# STM32F303xE register map
File version: 1.0
Registers are 32-bit, read-write, reset 0x0 unless marked. A register's access mark holds for its fields unless they carry their own. Offsets are from the block's base; [hi:lo] are bit positions; {n}, {i} and the like mark numbered series; 'fields as' and 'values as' point back to an identical list.

## GPIOA — General Purpose I/O
Base 0x48000000
Same registers: GPIOB 0x48000400, GPIOC 0x48000800, GPIOD 0x48000C00, GPIOE 0x48001000, GPIOF 0x48001400, GPIOG 0x48001800, GPIOH 0x48001C00
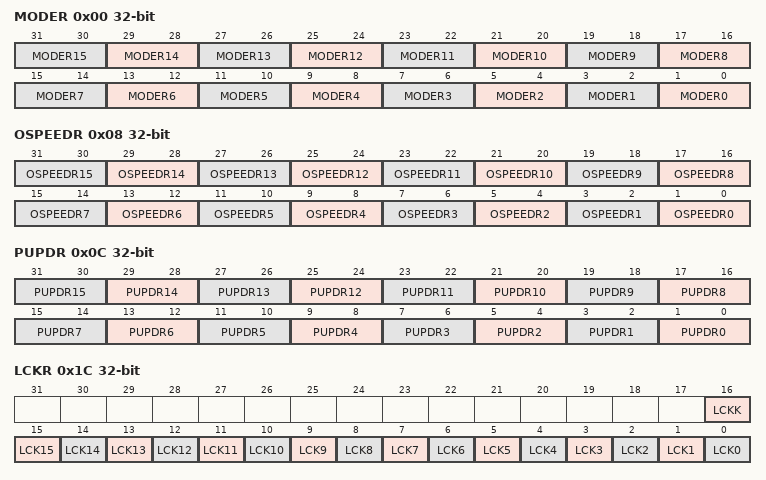
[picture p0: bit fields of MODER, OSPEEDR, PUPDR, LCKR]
0x00 MODER — GPIO port mode register
  [2n+1:2n] MODER{n} (n=0..15)
0x04 OTYPER — GPIO port output type register
0x08 OSPEEDR — GPIO port output speed register
  [2n+1:2n] OSPEEDR{n} (n=0..15)
0x0C PUPDR — GPIO port pull-up/pull-down register
  [2n+1:2n] PUPDR{n} (n=0..15)
0x10 IDR — GPIO port input data register
0x14 ODR — GPIO port output data register
0x18 BSRR — GPIO port bit set/reset register
0x1C LCKR — GPIO port configuration lock register
  [16] LCKK, [n] LCK{n} (n=0..15)
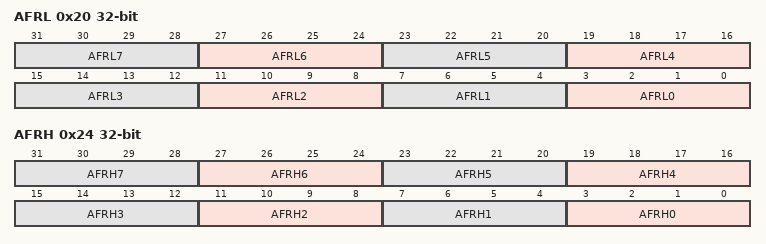
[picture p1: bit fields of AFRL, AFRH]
0x20 AFRL — GPIO alternate function registers
  [4n+3:4n] AFRL{n} (n=0..7)
0x24 AFRH — GPIO alternate function registers
  [4n+3:4n] AFRH{n} (n=0..7)
0x28 BRR — GPIO bit reset register

## FMC_Bank2_3 — Flexible Memory Controller Bank2
Base 0xA0000060
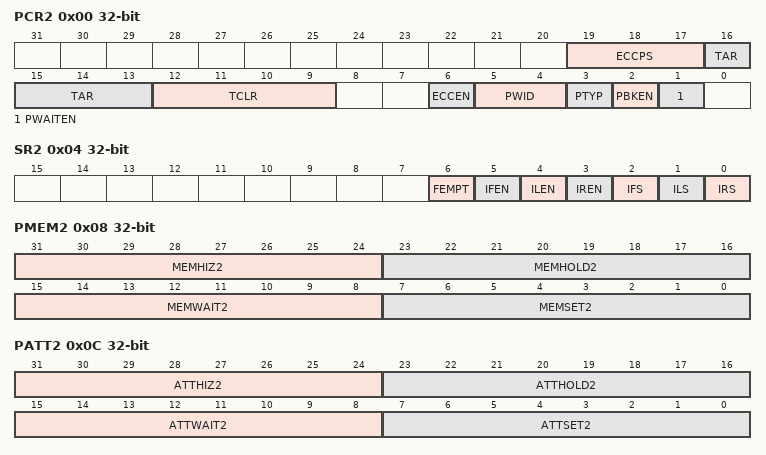
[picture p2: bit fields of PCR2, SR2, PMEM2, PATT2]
0x00 PCR2 — NAND Flash control register 2
  [19:17] ECCPS — ECCPS[1:0] bits (ECC page size)
  [16:13] TAR — TAR[3:0] bits (ALE to RE delay)
  [12:9] TCLR — TCLR[3:0] bits (CLE to RE delay)
  [6] ECCEN — ECC computation logic enable bit
  [5:4] PWID — PWID[1:0] bits (NAND Flash databus width)
  [3] PTYP — Memory type
  [2] PBKEN — PC Card/NAND Flash memory bank enable bit
  [1] PWAITEN — Wait feature enable bit
0x04 SR2 — NAND Flash FIFO status and interrupt register 2
  [6] FEMPT — FIFO empty
  [5] IFEN — Interrupt Falling Edge detection Enable bit
  [4] ILEN — Interrupt Level detection Enable bit
  [3] IREN — Interrupt Rising Edge detection Enable bit
  [2] IFS — Interrupt Falling Edge status
  [1] ILS — Interrupt Level status
  [0] IRS — Interrupt Rising Edge status
0x08 PMEM2 — NAND Flash Common memory space timing register 2
  [31:24] MEMHIZ2 — MEMHIZ2[7:0] bits (Common memory 2 databus HiZ time)
  [23:16] MEMHOLD2 — MEMHOLD2[7:0] bits (Common memory 2 hold time)
  [15:8] MEMWAIT2 — MEMWAIT2[7:0] bits (Common memory 2 wait time)
  [7:0] MEMSET2 — MEMSET2[7:0] bits (Common memory 2 setup time)
0x0C PATT2 — NAND Flash Attribute memory space timing register 2
  [31:24] ATTHIZ2 — ATTHIZ2[7:0] bits (Attribute memory 2 databus HiZ time)
  [23:16] ATTHOLD2 — ATTHOLD2[7:0] bits (Attribute memory 2 hold time)
  [15:8] ATTWAIT2 — ATTWAIT2[7:0] bits (Attribute memory 2 wait time)
  [7:0] ATTSET2 — ATTSET2[7:0] bits (Attribute memory 2 setup time)
0x14 ECCR2 — NAND Flash ECC result registers 2
  [31:0] ECC2 — ECC result
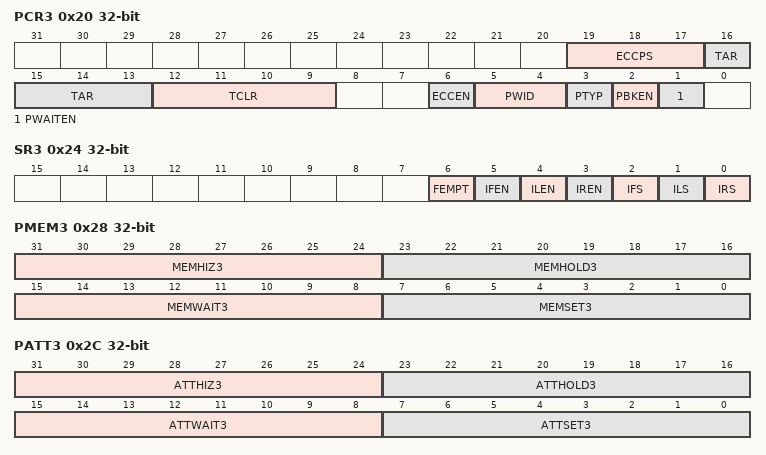
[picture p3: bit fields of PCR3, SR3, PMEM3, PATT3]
0x20 PCR3 — NAND Flash control register 3
  [19:17] ECCPS — ECCPS[2:0] bits (ECC page size)
  [16:13] TAR — TAR[3:0] bits (ALE to RE delay)
  [12:9] TCLR — TCLR[3:0] bits (CLE to RE delay)
  [6] ECCEN — ECC computation logic enable bit
  [5:4] PWID — PWID[1:0] bits (NAND Flash databus width)
  [3] PTYP — Memory type
  [2] PBKEN — PC Card/NAND Flash memory bank enable bit
  [1] PWAITEN — Wait feature enable bit
0x24 SR3 — NAND Flash FIFO status and interrupt register 3
  fields as SR2
0x28 PMEM3 — NAND Flash Common memory space timing register 3
  [31:24] MEMHIZ3 — MEMHIZ3[7:0] bits (Common memory 3 databus HiZ time)
  [23:16] MEMHOLD3 — MEMHOLD3[7:0] bits (Common memory 3 hold time)
  [15:8] MEMWAIT3 — MEMWAIT3[7:0] bits (Common memory 3 wait time)
  [7:0] MEMSET3 — MEMSET3[7:0] bits (Common memory 3 setup time)
0x2C PATT3 — NAND Flash Attribute memory space timing register 3
  [31:24] ATTHIZ3 — ATTHIZ3[7:0] bits (Attribute memory 3 databus HiZ time)
  [23:16] ATTHOLD3 — ATTHOLD3[7:0] bits (Attribute memory 3 hold time)
  [15:8] ATTWAIT3 — ATTWAIT3[7:0] bits (Attribute memory 3 wait time)
  [7:0] ATTSET3 — ATTSET3[7:0] bits (Attribute memory 3 setup time)
0x34 ECCR3 — NAND Flash ECC result registers 3
  [31:0] ECC3 — ECC result

## FMC_Bank1E — Flexible Memory Controller Bank1E
Base 0xA0000104
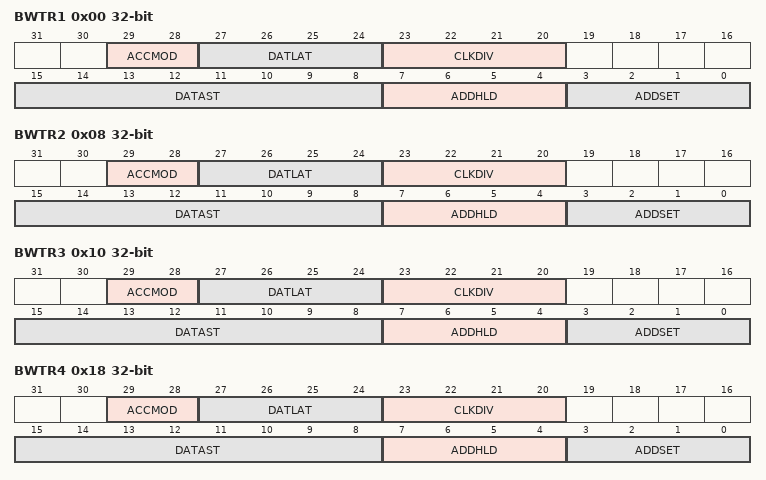
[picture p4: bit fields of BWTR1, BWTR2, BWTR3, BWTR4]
0x00 BWTR1 — NOR/PSRAM write timing registers
  [29:28] ACCMOD — ACCMOD[1:0] bits (Access mode)
  [27:24] DATLAT — DATLA[3:0] bits (Data latency)
  [23:20] CLKDIV — CLKDIV[3:0] bits (Clock divide ratio)
  [15:8] DATAST — DATAST [3:0] bits (Data-phase duration)
  [7:4] ADDHLD — ADDHLD[3:0] bits (Address-hold phase duration)
  [3:0] ADDSET — ADDSET[3:0] bits (Address setup phase duration)
0x08 BWTR2 — NOR/PSRAM write timing registers
  fields as BWTR1
0x10 BWTR3 — NOR/PSRAM write timing registers
  fields as BWTR1
0x18 BWTR4 — NOR/PSRAM write timing registers
  fields as BWTR1

## DBGMCU — Debug MCU
Base 0xE0042000
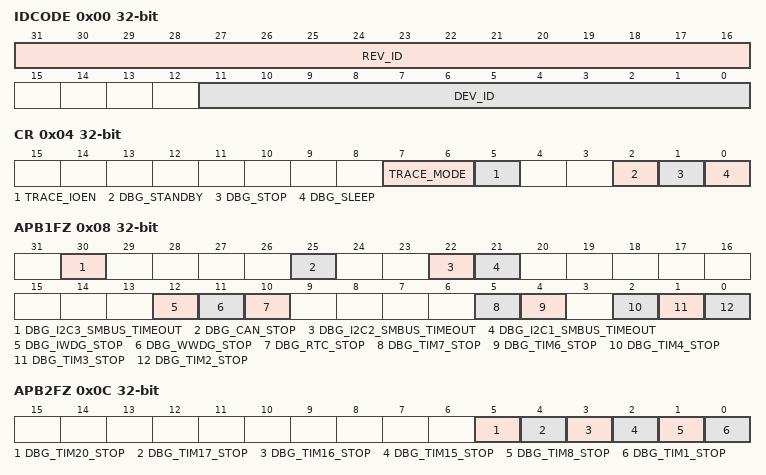
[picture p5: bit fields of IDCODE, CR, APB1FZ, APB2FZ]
0x00 IDCODE — MCU device ID code
  [31:16] REV_ID, [11:0] DEV_ID
0x04 CR — Debug MCU configuration register
  [7:6] TRACE_MODE, [5] TRACE_IOEN, [2] DBG_STANDBY, [1] DBG_STOP, [0] DBG_SLEEP
0x08 APB1FZ — Debug MCU APB1 freeze register
  [30] DBG_I2C3_SMBUS_TIMEOUT, [25] DBG_CAN_STOP, [22] DBG_I2C2_SMBUS_TIMEOUT, [21] DBG_I2C1_SMBUS_TIMEOUT, [12] DBG_IWDG_STOP, [11] DBG_WWDG_STOP, [10] DBG_RTC_STOP, [5] DBG_TIM7_STOP, [4] DBG_TIM6_STOP, [2] DBG_TIM4_STOP, [1] DBG_TIM3_STOP, [0] DBG_TIM2_STOP
0x0C APB2FZ — Debug MCU APB2 freeze register
  [5] DBG_TIM20_STOP, [4] DBG_TIM17_STOP, [3] DBG_TIM16_STOP, [2] DBG_TIM15_STOP, [1] DBG_TIM8_STOP, [0] DBG_TIM1_STOP
